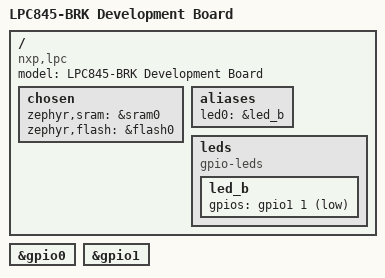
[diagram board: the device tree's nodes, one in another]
/dts-v1/;
#include <nxp/nxp_lpc845.dtsi>
#include <dt-bindings/gpio/gpio.h>

/ {
	model = "LPC845-BRK Development Board";
	compatible = "nxp,lpc";

	chosen {
		zephyr,sram    = &sram0;
		zephyr,flash   = &flash0;
	};

	aliases {
		led0 = &led_b;
	};

	leds {
		compatible = "gpio-leds";
		led_b: led_b { gpios = <&gpio1 1 GPIO_ACTIVE_LOW>; };
		status = "okay";
	};
};

&gpio0 {
	status = "okay";
};

&gpio1 {
	status = "okay";
};
